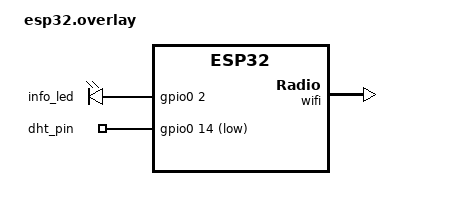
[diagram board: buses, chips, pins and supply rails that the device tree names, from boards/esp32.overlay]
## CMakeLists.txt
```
# SPDX-License-Identifier: Apache-2.0

cmake_minimum_required(VERSION 3.20.0)

find_package(Zephyr REQUIRED HINTS $ENV{ZEPHYR_BASE})
project(wlab_station)

target_include_directories(app PRIVATE inc)

target_sources(app PRIVATE 
    main.c
    src/wifi_net.c
    src/mqtt_worker.c
    src/wlab.c
    src/dht2x.c
    src/wdg.c
    src/nvs_data.c
    src/timestamp.c
    src/shell_commands.c
)
```

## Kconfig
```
source "Kconfig.zephyr"

config TIMESTAMP_UPDATE_PERIOD_SEC
	int "Period between sntp synchronization"
	default 60

config WDG_TIMEOUT_SEC
	int "Watchdoog timeout"
	default 30

config WIFI_FIRST_CONN_TIMEOUT_SEC
	int "Timeout for first wifi connection"
	default 20

config MQTT_FIRST_CONN_TIMEOUT_SEC
	int "Timeout for first mqtt connection"
	default 20

config MQTT_KEEPALIVE_TIMEOUT_MINS
	int "The longest time with no keepalive response from server"
	default 10

config BUFF_MAX_STRING_LEN
	int "Maximum length for wifi_ssid, wifi_pass, mqtt_broker or wlab name"
	default 32
```

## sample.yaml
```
sample:
  description: wlab station sample, the simplest Zephyr
    application
  name: wlab_station
common:
  tags: introduction
  integration_platforms:
    - native_posix
  harness: console
  harness_config:
    type: one_line
    regex:
      - "wlab station! (.*)"
tests:
  sample.basic.helloworld:
    tags: introduction
```

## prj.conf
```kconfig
#
# prj.conf
#
CONFIG_LOG=y
CONFIG_LOG_MODE_DEFERRED=y
CONFIG_COMMON_LIBC_MALLOC_ARENA_SIZE=16384
CONFIG_HEAP_MEM_POOL_SIZE=32768
CONFIG_SYSTEM_WORKQUEUE_STACK_SIZE=2048
CONFIG_MAIN_STACK_SIZE=2048

CONFIG_GPIO=y
CONFIG_MQTT_LIB=y
CONFIG_SNTP=y
CONFIG_WIFI=y
CONFIG_INIT_STACKS=y
CONFIG_NET_L2_WIFI_MGMT=y
CONFIG_WATCHDOG=y
CONFIG_WDT_DISABLE_AT_BOOT=n
CONFIG_FLASH=n
CONFIG_FLASH_PAGE_LAYOUT=n
CONFIG_NVS=n
CONFIG_MPU_ALLOW_FLASH_WRITE=y
CONFIG_NVS_LOG_LEVEL_INF=n

CONFIG_NETWORKING=y
CONFIG_NET_IPV4=y
CONFIG_NET_IPV6=n
CONFIG_NET_UDP=y
CONFIG_NET_TCP=y
CONFIG_DNS_RESOLVER=y
CONFIG_DNS_RESOLVER_AI_MAX_ENTRIES=10
CONFIG_DNS_SERVER_IP_ADDRESSES=y
CONFIG_DNS_SERVER1="8.8.8.8"

CONFIG_NET_SOCKETS=y
CONFIG_NET_DHCPV4=y
CONFIG_NET_CONFIG_SETTINGS=y
CONFIG_NET_TX_STACK_SIZE=2048
CONFIG_NET_RX_STACK_SIZE=2048
CONFIG_NET_PKT_RX_COUNT=8
CONFIG_NET_PKT_TX_COUNT=8
CONFIG_NET_BUF_RX_COUNT=12
CONFIG_NET_BUF_TX_COUNT=12
CONFIG_NET_MAX_CONTEXTS=10

# Added to prevent error with missing #include <ethernet/eth_stats.h> for esp_wifi_drv.c
# Adding this line will cause CMAKE Warning: No SOURCES given to Zephyr library: drivers__ethernet
# Just ignore.
CONFIG_NET_L2_ETHERNET=y
```

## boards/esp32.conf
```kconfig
CONFIG_ESP_HEAP_MEM_POOL_REGION_1_SIZE=16384
```

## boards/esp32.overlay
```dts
/ {
    leds {
        compatible = "gpio-leds";
        info_led: info_led {
            gpios = <&gpio0 2 GPIO_ACTIVE_HIGH>;
        };
    };

    dht {
        compatible = "gpio-leds";
        dht_pin: dht_pin {
            gpios = <&gpio0 14 (GPIO_PULL_UP | GPIO_ACTIVE_LOW)>;
        };
    };
};

&wifi {
	status = "okay";
};
```

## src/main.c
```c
/* ---------------------------------------------------------------------------
 *  wlab_station
 * ---------------------------------------------------------------------------
 *  Name: main.c
 * --------------------------------------------------------------------------*/
#include <stdint.h>
#include <zephyr/device.h>
#include <zephyr/drivers/flash.h>
#include <zephyr/drivers/gpio.h>
#include <zephyr/drivers/watchdog.h>
#include <zephyr/fs/nvs.h>
#include <zephyr/kernel.h>
#include <zephyr/logging/log.h>
#include <zephyr/net/mqtt.h>
#include <zephyr/net/sntp.h>
#include <zephyr/storage/flash_map.h>

#include "config_wifi.h"
#include "config_wlab.h"
#include "dht2x.h"
#include "mqtt_worker.h"
#include "nvs_defs.h"
#include "version.h"
#include "wifi_net.h"
#include "wlab.h"

LOG_MODULE_REGISTER(MAIN, LOG_LEVEL_DBG);

static const struct gpio_dt_spec InfoLed =
    GPIO_DT_SPEC_GET(DT_NODELABEL(info_led), gpios);

static const struct device *const Wdt = DEVICE_DT_GET(DT_ALIAS(watchdog0));

static int64_t UptimeSyncMs = 0;
static int64_t SntpSyncSec = 0;
static struct nvs_fs Fs = {0};

static int64_t rtc_time_get(void) {
    int64_t sec_elapsed = (k_uptime_get() - UptimeSyncMs) / 1000;
    return (SntpSyncSec + sec_elapsed);
}

static int32_t rtc_time_sync(void) {
    int32_t rc = 0;
    struct sntp_time sntp_time = {0};

    rc = sntp_simple("0.pl.pool.ntp.org", 2000, &sntp_time);
    if (0 == rc) {
        SntpSyncSec = (int64_t)sntp_time.seconds;
        UptimeSyncMs = k_uptime_get();
    } else {
        LOG_ERR("Failed to acquire SNTP, code %d", rc);
    }

    return (rc);
}

int main(void) {
    LOG_INF("WLAB station board: %s", CONFIG_BOARD);
    LOG_INF("sys_clock_hw_cycles_per_sec = %u", sys_clock_hw_cycles_per_sec());

    if (!device_is_ready(Wdt)) {
        LOG_ERR("%s: device not ready", Wdt->name);
        while (true)
            ;
    }

    struct wdt_timeout_cfg wdt_config = {
        /* Reset SoC when watchdog timer expires. */
        .flags = WDT_FLAG_RESET_SOC,

        /* Expire watchdog after max window */
        .window.min = 0,         /* for esp32 it has to be 0 */
        .window.max = 32 * 1000, /* millis */
        .callback = NULL,
    };

    int32_t wdt_channel_id = wdt_install_timeout(Wdt, &wdt_config);
    if (wdt_channel_id < 0) {
        LOG_ERR("Watchdog install error");
        while (true)
            ;
    }

    int32_t ret = wdt_setup(Wdt, WDT_OPT_PAUSE_HALTED_BY_DBG);
    if (ret < 0) {
        LOG_ERR("Watchdog setup error");
        while (true)
            ;
    }
    LOG_INF("FIRMWARE_VERSION %s", FIRMWARE_VERSION);
    LOG_INF("ZEPHYR_VERSION %s", ZEPHYR_VERSION);

    ret = gpio_pin_configure_dt(&InfoLed, GPIO_OUTPUT_ACTIVE);
    if (0 != ret) {
        LOG_ERR("gpio configuration failed");
        while (true)
            ;
    }

    if (!device_is_ready(InfoLed.port)) {
        LOG_ERR("GPIO0 not ready");
        while (true)
            ;
    }

    mqtt_worker_init(CONFIG_WLAB_MQTT_BROKER, CONFIG_WLAB_MQTT_BROKER_PORT,
                     NULL, NULL);

    wifi_net_init(WIFI_SSID, WIFI_PASS);

    if (0 != mqtt_worker_connection_wait(8 * 1000)) {
        /* system reboot by wdg */
        while (true)
            ;
    }

    wlab_init();

    int32_t auth_attempts = 0;
    while (0 != wlab_authorize()) {
        auth_attempts++;
        wdt_feed(Wdt, wdt_channel_id);
        if (8 == auth_attempts) {
            /* system reboot by wdg */
            while (true)
                ;
        }
    }
    LOG_INF("wlab authorize success");

    int32_t sntp_sync_attempts = 0;
    while (0 != rtc_time_sync()) {
        sntp_sync_attempts++;
        wdt_feed(Wdt, wdt_channel_id);
        if (8 == sntp_sync_attempts) {
            /* system reboot by wdg */
            while (true)
                ;
        }
    }
    LOG_INF("rtc sync success");

    int64_t last_rtc_sync_ts = rtc_time_get();
    int64_t ts_now = 0;
    for (;;) {
        k_sleep(K_MSEC(100));

        ts_now = rtc_time_get();

        wlab_process(ts_now);

        if (ts_now - last_rtc_sync_ts > 1 * 60) {
            rtc_time_sync();
            last_rtc_sync_ts = ts_now;
        }

        gpio_pin_toggle_dt(&InfoLed);

        int64_t last_mqtt_alive = mqtt_worker_last_keepalive_resp();
        int64_t mqtt_alive_timeout = 8 * (1000 * MQTT_WORKER_PING_TIMEOUT);
        if (k_uptime_get() > last_mqtt_alive + mqtt_alive_timeout) {
            k_sleep(K_FOREVER);
        } else {
            wdt_feed(Wdt, wdt_channel_id);
        }
    }
}

/* ---------------------------------------------------------------------------
 * end of file
 * --------------------------------------------------------------------------*/
```

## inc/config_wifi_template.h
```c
/* ---------------------------------------------------------------------------
 *  wlab_station
 * ---------------------------------------------------------------------------
 *  Name: config_wifi.h
 * --------------------------------------------------------------------------*/
#ifndef CONFIG_WIFI_H_
#define CONFIG_WIFI_H_

#define WIFI_SSID "wifi_net_ssid"
#define WIFI_PASS "Abb1234"

#endif /* CONFIG_WIFI_H_ */
/* ---------------------------------------------------------------------------
 * end of file
 * --------------------------------------------------------------------------*/
```

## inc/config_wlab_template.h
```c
/* ---------------------------------------------------------------------------
 *  wlab_station
 * ---------------------------------------------------------------------------
 *  Name: config_wlab.h
 * --------------------------------------------------------------------------*/
#ifndef WLAB_CONFIG_H_
#define WLAB_CONFIG_H_

#define CONFIG_WLAB_DHT_DESC ("DHT22")

#define CONFIG_WLAB_PUB_PERIOD     (10) /* minutes */
#define CONFIG_WLAB_MEASURE_PERIOD (4)  /* secs */

#define CONFIG_WLAB_PUB_TOPIC  ("/testsamples")
#define CONFIG_WLAB_AUTH_TOPIC ("/testauth")

#define CONFIG_WLAB_NAME      ("Station Name")
#define CONFIG_WLAB_LATITIUDE ("40")
#define CONFIG_WLAB_LONGITUDE ("30")
#define CONFIG_WLAB_TIMEZONE  ("Europe/Warsaw")

#define CONFIG_WLAB_MQTT_BROKER      ("mqtt://hostname")
#define CONFIG_WLAB_MQTT_BROKER_PORT (1883)

#endif /* WLAB_CONFIG_H_ */
/* ---------------------------------------------------------------------------
 * end of file
 * --------------------------------------------------------------------------*/
```

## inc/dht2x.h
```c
/* ---------------------------------------------------------------------------
 *  wlab_station
 * ---------------------------------------------------------------------------
 *  Name: dht2x.h
 * --------------------------------------------------------------------------*/
#ifndef DHT2X_H_
#define DHT2X_H_

#include <stdint.h>
#include <zephyr/drivers/gpio.h>

/**
 * @brief Initialize custom implementation of dht sensors
 *
 * @param dhtx_spec const struct gpio_dt_spec *
 * @return int 0 - success, errno code otherwise
 */
int dht2x_init(const struct gpio_dt_spec *dhtx_spec);

/**
 * @brief Read DHTxy sensor value using interrupt service runtime, not blocking
 * for rtos
 *
 * @param dhtx_spec const struct gpio_dt_spec *
 * @param temp Pointer to temperature value
 * @param rh Pointer to humidity value
 * @return int 0 - success, errno code otherwise
 */
int dht2x_read(const struct gpio_dt_spec *dhtx_spec, int16_t *temp,
               int16_t *rh);

#endif /* DHT2X_H_ */
/* ---------------------------------------------------------------------------
 * end of file
 * --------------------------------------------------------------------------*/
```

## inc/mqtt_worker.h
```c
/* ---------------------------------------------------------------------------
 *  wlab_station
 * ---------------------------------------------------------------------------
 *  Name: mqtt_worker.h
 * --------------------------------------------------------------------------*/
#ifndef MQTT_WORKER_H_
#define MQTT_WORKER_H_

#include <stdint.h>
#include <zephyr/net/mqtt.h>

#define MQTT_WORKER_CLIENT_ID           ("zephyrux")
#define MQTT_WORKER_MAX_TOPIC_LEN       (128)
#define MQTT_WORKER_MAX_PAYLOAD_LEN     (256)
#define MQTT_WORKER_MAX_PUBLISH_LEN     (512)
#define MQTT_WORKER_PUBLISH_ACK_TIMEOUT (4) /* seconds */

typedef void (*subs_cb_t)(char *topic, uint16_t topic_len, char *payload,
                          uint16_t payload_len);

/**
 * @brief Initialize worker. All next action will be executed in separated
 * thread. Function is not blocked, to verify if driver is connected with broker
 * use api below.
 * @param hostname It can be name of host or string representation of ip addr.
 * @param port Broker port
 * @param ping_period Ping request period
 * @param max_ping_no_answer Max time when ping haven't got
 * @param subs Pointer to list of topics to be subscribed, NULL if no topics
 * should be subcribed
 * @param subs_cb Function to handle data incomming to subscribed topics, NULL
 * if not needed.
 */
void mqtt_worker_init(const char *hostname, int32_t port, uint32_t ping_period,
                      uint32_t max_ping_no_answer,
                      struct mqtt_subscription_list *subs, subs_cb_t subs_cb);

/**
 * @brief Publish data to given topic. Use in the same way as typical printf().
 * @param topic Topic where msg will be published
 * @return Negative errno code
 */
int mqtt_worker_publish_qos1(const char *topic, const char *fmt, ...);

/**
 * @brief Test if last keepalive response is longer than
 * CONFIG_MQTT_KEEPALIVE_TIMEOUT_MINS, if yes, then reboot device.
 *
 */
void mqtt_worker_keepalive_test(void);

#endif /* MQTT_WORKER_H_ */
/* ---------------------------------------------------------------------------
 * end of file
 * --------------------------------------------------------------------------*/
```

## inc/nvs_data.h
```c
/* ---------------------------------------------------------------------------
 *  wlab_station
 * ---------------------------------------------------------------------------
 *  Name: nvs_data.h
 * --------------------------------------------------------------------------*/
#ifndef NVS_DATA_H_
#define NVS_DATA_H_

#include <stdint.h>
#include <zephyr/device.h>

#define NVS_PARTITION        storage_partition
#define NVS_PARTITION_DEVICE FIXED_PARTITION_DEVICE(NVS_PARTITION)
#define NVS_PARTITION_OFFSET FIXED_PARTITION_OFFSET(NVS_PARTITION)
#define NVS_PARTITION_SIZE   FIXED_PARTITION_SIZE(NVS_PARTITION)

#define NVS_ID_BOOT_COUNT        (1)
#define NVS_ID_WIFI_CONFIG       (2)
#define NVS_ID_MQTT_CONFIG       (3)
#define NVS_ID_WLAB_DEVICE_ID    (4)
#define NVS_ID_WLAB_NAME         (5)
#define NVS_ID_WLAB_GPS_POSITION (6)
#define NVS_ID_WLAB_PUB_PERIOD   (7)

struct wifi_config {
    char wifi_ssid[CONFIG_BUFF_MAX_STRING_LEN];
    char wifi_pass[CONFIG_BUFF_MAX_STRING_LEN];
};

struct mqtt_config {
    char mqtt_broker[CONFIG_BUFF_MAX_STRING_LEN];
    uint32_t mqtt_port;
    uint32_t mqtt_ping_period;        /* secs */
    uint32_t mqtt_max_ping_no_answer; /* mins */
};

struct gps_position {
    float latitude;
    float longitude;
    char timezone[CONFIG_BUFF_MAX_STRING_LEN];
};

/**
 * @brief Initialise none volatile storage space.
 *
 */
void nvs_data_init(void);

/**
 * @brief Read wifi settings data, save in dst pointer
 *
 * @param wificonf Pointer to save settings.
 */
void nvs_data_wifi_config_get(struct wifi_config *wificonf);

/**
 * @brief Save wifi settings data
 *
 * @param wificonf Pointer to save settings.
 */
int nvs_data_wifi_config_set(struct wifi_config *wificonf);

/**
 * @brief Read mqtt settings data, save in dst pointer
 *
 * @param dst Pointer to save settings.
 */
void nvs_data_mqtt_config_get(struct mqtt_config *dst);

/**
 * @brief Save mqtt settings data.
 *
 * @param mqttconf Pointer with data do save
 */
int nvs_data_mqtt_config_set(struct mqtt_config *mqttconf);

/**
 * @brief Read wlab device id, if not exists, save UINT64_MAX
 *
 * @param device_id Pointer to save device_id.
 */
void nvs_data_wlab_device_id_get(uint64_t *device_id);

/**
 * @brief Save wlab device id.
 *
 * @param device_id Pointer with data do save
 */
int nvs_data_wlab_device_id_set(uint64_t *device_id);

/**
 * @brief Read wlab name, if not exists, copy WLAB_STATION to dst as default
 * value.
 *
 * @param wlab_name Destination of wlab_name with min size
 * CONFIG_BUFF_MAX_STRING_LEN
 */
void nvs_data_wlab_name_get(char *wlab_name);

/**
 * @brief Save wlab name.
 *
 * @param wlab_name Pointer with data do save
 */
int nvs_data_wlab_name_set(char *wlab_name);

/**
 * @brief Read wlab gps position, if not exists, read and save default datata
 *
 * @param gps_pos Destination of wlab gps position
 */
void nvs_data_wlab_gps_position_get(struct gps_position *gps_pos);

/**
 * @brief Save wlab gps position.
 *
 * @param gps_pos Pointer with data do save
 */
int nvs_data_wlab_gps_position_set(struct gps_position *gps_pos);

/**
 * @brief Read wlab publish period.
 *
 * @param pub_period Destination of wlab gps position
 */
void nvs_data_wlab_pub_period_get(uint32_t *pub_period);

/**
 * @brief Save wlab publish period.
 *
 * @param pub_period Pointer with data do save
 */
int nvs_data_wlab_pub_period_set(uint32_t *pub_period);

#endif /* NVS_DATA_H_ */
/* ---------------------------------------------------------------------------
 * end of file
 * --------------------------------------------------------------------------*/
```

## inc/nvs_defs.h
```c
/* ---------------------------------------------------------------------------
 *  nvs
 * ---------------------------------------------------------------------------
 *  Name: nvs_defs.h
 * --------------------------------------------------------------------------*/
#ifndef NVS_DEFS_H_
#define NVS_DEFS_H_

#define NVS_PARTITION        storage_partition
#define NVS_PARTITION_DEVICE FIXED_PARTITION_DEVICE(NVS_PARTITION)
#define NVS_PARTITION_OFFSET FIXED_PARTITION_OFFSET(NVS_PARTITION)
#define NVS_PARTITION_SIZE   FIXED_PARTITION_SIZE(NVS_PARTITION)

#define NVS_ID_BOOT_COUNT (1)
#define NVS_ID_TIMESTAMP  (2)

#endif /* NVS_DEFS_H_ */
/* ---------------------------------------------------------------------------
 * end of file
 * --------------------------------------------------------------------------*/
```

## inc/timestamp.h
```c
/* ---------------------------------------------------------------------------
 *  wlab_station
 * ---------------------------------------------------------------------------
 *  Name: timestamp.h
 * --------------------------------------------------------------------------*/
#ifndef TIMESTAMP_H_
#define TIMESTAMP_H_

#include <stdint.h>

/**
 * @brief Initialize timestamp module, use sntp to get real epoch time. When no
 * possibilities to sync time - reboot cpu.
 *
 */
void timestamp_init(void);

/**
 * @brief Actual epoch timestamp.
 *
 * @return int64_t Actual epoch timestamp millis.
 */
int64_t timestamp_get(void);

/**
 * @brief Update internal timer to be up-to-date with epoch time.
 *
 */
void timestamp_update(void);

#endif /* TIMESTAMP_H_ */
/* ---------------------------------------------------------------------------
 * end of file
 * --------------------------------------------------------------------------*/
```

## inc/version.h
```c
/* ---------------------------------------------------------------------------
 *  wlab_station
 * ---------------------------------------------------------------------------
 *  Name: version.h
 * --------------------------------------------------------------------------*/
#ifndef VERSION_H_
#define VERSION_H_

#define FIRMWARE_VERSION "1.1"

#endif /* VERSION_H_ */
/* ---------------------------------------------------------------------------
 * end of file
 * --------------------------------------------------------------------------*/
```

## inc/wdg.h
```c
/* ---------------------------------------------------------------------------
 *  wlab_station
 * ---------------------------------------------------------------------------
 *  Name: wdg.h
 * --------------------------------------------------------------------------*/
#ifndef WDG_H_
#define WDG_H_

#include <stdint.h>

/**
 * @brief Feed watchdog.
 *
 */
void wdg_feed(void);

/**
 * @brief Initialise watchdog with timeout passed in seconds.
 *
 */
void wdg_init(uint32_t timeout_sec);

#endif /* WDG_H_ */
/* ---------------------------------------------------------------------------
 * end of file
 * --------------------------------------------------------------------------*/
```

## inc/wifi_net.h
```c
/* ---------------------------------------------------------------------------
 *  wlab_station
 * ---------------------------------------------------------------------------
 *  Name: wifi_net.h
 * --------------------------------------------------------------------------*/
#ifndef WIFI_NET_H_
#define WIFI_NET_H_

/**
 * @brief Initialize wifi network, everything is proceeded in background, do
 * reconnection if needed
 *
 * @param ssid Network ssid string
 * @param passwd Network passwd string, provide NULL if network is open
 */
void wifi_net_init(char *ssid, char *passwd);

/**
 * @brief Get wifi interface MAC address
 *
 * @param mac_buffer buffer for mac address, will be ended with \0 sign
 */
void net_mac_string(char mac_buffer[13]);

/**
 * @brief Register callback to notify network disconnected event.
 *
 * @param disco_cb Cb to register.
 */
void net_on_disconnect_reqister(void (*disco_cb)(int reason));

#endif /* WIFI_NET_H_ */
/* ---------------------------------------------------------------------------
 * end of file
 * --------------------------------------------------------------------------*/
```

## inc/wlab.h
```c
/* ---------------------------------------------------------------------------
 *  wlab_station
 * ---------------------------------------------------------------------------
 *  Name: wlab.h
 * --------------------------------------------------------------------------*/
#ifndef WLAB_H_
#define WLAB_H_

#include <stdint.h>

/**
 * @brief Initialize weatherlab service with provided sensor type
 *
 */
void wlab_init(void);

/**
 * @brief Do sensor measurement and publish to weatherlab if needed
 *
 * @param timestamp_secs Actual epoch time in seconds
 */
void wlab_process(int64_t timestamp_secs);

#endif /* WLAB_H_ */
/* ---------------------------------------------------------------------------
 * end of file
 * --------------------------------------------------------------------------*/
```

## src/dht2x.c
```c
/* ---------------------------------------------------------------------------
 *  wlab_station
 * ---------------------------------------------------------------------------
 *  Name: dht2x.h
 * --------------------------------------------------------------------------*/
#include "dht2x.h"

#include <errno.h>
#include <stdint.h>
#include <zephyr/device.h>
#include <zephyr/drivers/gpio.h>
#include <zephyr/kernel.h>
#include <zephyr/logging/log.h>

LOG_MODULE_REGISTER(DHTx, LOG_LEVEL_DBG);

struct gpio_callback IrqCb;
K_SEM_DEFINE(DhtReadDone, 0, 1);

static volatile uint32_t PulseStartUs = 0;
static volatile uint32_t PulseCnt = 0;
static volatile uint64_t ReadData = 0;
static volatile uint32_t LastElapsed = 0;

static uint32_t dht2x_us_now(void) {
    uint64_t cyc = k_cycle_get_32();
    uint64_t cyc_per_us =
        ((uint32_t)sys_clock_hw_cycles_per_sec()) / (uint32_t)USEC_PER_SEC;
    return (cyc / cyc_per_us);
}

static void gpio_callback(const struct device *dev, struct gpio_callback *cb,
                          uint32_t pin) {
    /* DHT21 = AM2301 sends 64 bit, only first 40bis include data */
    uint32_t us_now = dht2x_us_now();
    LastElapsed = us_now - PulseStartUs;
    if (0 == PulseCnt) {
        if (LastElapsed > 100) {
            PulseCnt += 2;
            /* Sometime we are not able to catch first falling edge, if this
             * situation occure then second elapsed is ~180us. First edge
             * should be < 30us */
        }
    } else if (1 == PulseCnt) {
        PulseCnt++;
    } else {
        if (LastElapsed <= 110) { /* bit 0 */
            ReadData = ReadData << 1;
        } else if (LastElapsed > 110) { /* bit 1 */
            ReadData = (ReadData << 1) | 1;
        } else { /* bit timing failed */
            gpio_pin_interrupt_configure(dev, pin, GPIO_INT_DISABLE);
            k_sem_give(&DhtReadDone);
        }
        PulseCnt++;
    }

    if (42 == PulseCnt) {
        /* read success */
        gpio_pin_interrupt_configure(dev, pin, GPIO_INT_DISABLE);
        k_sem_give(&DhtReadDone);
    }

    PulseStartUs = us_now;
}

int dht2x_init(const struct gpio_dt_spec *dhtx_spec) {
    if (!device_is_ready(dhtx_spec->port)) {
        LOG_ERR("Dht2x gpio not ready");
        return -EIO;
    }

    return gpio_pin_configure_dt(dhtx_spec, GPIO_OUTPUT_INACTIVE);
}

int dht2x_read(const struct gpio_dt_spec *dhtx_spec, int16_t *temp,
               int16_t *rh) {
    int ret = 0;
    LOG_DBG("%s", __FUNCTION__);

    k_sem_take(&DhtReadDone, K_NO_WAIT);
    PulseCnt = 0;
    ReadData = 0;

    gpio_pin_configure_dt(dhtx_spec, GPIO_OUTPUT_INACTIVE);

    /* assert to send start signal */
    gpio_pin_set_dt(dhtx_spec, true);

    k_sleep(K_MSEC(18));

    gpio_pin_set_dt(dhtx_spec, false);
    PulseStartUs = dht2x_us_now();

    gpio_pin_configure_dt(dhtx_spec, GPIO_INPUT);
    gpio_pin_interrupt_configure_dt(dhtx_spec, GPIO_INT_EDGE_FALLING);
    gpio_init_callback(&IrqCb, gpio_callback, BIT(dhtx_spec->pin));
    gpio_add_callback_dt(dhtx_spec, &IrqCb);

    ret = k_sem_take(&DhtReadDone, K_MSEC(50));
    if (0 != ret) {
        LOG_ERR("Read failed, PulseCnt %d", PulseCnt);
        ret = -EIO;
        goto read_done;
    } else {
        LOG_DBG("Read done, PulseCnt %d, LastElapsed %u, ReadData %010llX",
                PulseCnt, LastElapsed, ReadData);
    }

    uint8_t *buf = (uint8_t *)&ReadData;

    /* verify checksum */
    if (((buf[4] + buf[3] + buf[2] + buf[1]) & 0xFF) != buf[0] || 0 == buf[0]) {
        LOG_ERR("Invalid checksum in fetched sample");
        ret = -ENOTSUP;
        goto read_done;
    } else {
        LOG_DBG("Checksum valid");
    }

    *rh = (ReadData >> 24) & 0xFFFF;
    *temp = (ReadData >> 8) & 0xFFFF;

    if (*temp & (1 << 15)) {
        *temp &= ~(1 << 15);
        *temp = -*temp;
    }

read_done:
    gpio_pin_configure_dt(dhtx_spec, GPIO_OUTPUT_INACTIVE);
    return (ret);
}

/* ---------------------------------------------------------------------------
 * end of file
 * --------------------------------------------------------------------------*/
```
